# YTM32B1LE0 register map
Vendor: YTMicro; File version: 1.9
CPU: CM0PLUS r0p1, little endian, MPU, FPU, 2 interrupt priority bits
Registers are 32-bit, read-write, reset 0x0 unless marked. A register's access mark holds for its fields unless they carry their own. Offsets are from the block's base; [hi:lo] are bit positions; {n}, {i} and the like mark numbered series.

## PCTRLA — PORT Control
Base 0x40049000; register names take the prefix PCTRLA_
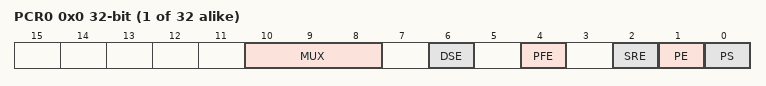
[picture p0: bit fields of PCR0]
{0x0+4i} PCR{i} (i=0..31) — Port control register
  [10:8] MUX — Not all pin muxing slots are implemented. Unimplemented pin muxing slots are reserved. Please refer to pinmux table for detailed peripheral functions. The corresponding pin is configured in the following pin muxing slot as follows:
    0=Alternative 0, analog function, digital function is disabled; 1=Alternative 1, GPIO function; {v}=Alternative {v} (v=2..7)
  [6] DSE — Drive strength configuration for digital pin muxing.
    0=Low drive strength, if the pin is configured as a digital output; 1=High drive strength, if the pin is configured as a digital output
  [4] PFE — Passive filter configuration for digital pin muxing.
    0=Passive input filter is disabled; 1=Passive input filter is enabled, if the pin is configured as a digital input
  [2] SRE — Slew rate configuration for digital pin muxing.
    0=Fast slew rate, if the pin is configured as a digital output; 1=Slow slew rate, if the pin is configured as a digital output
  [1] PE — Pull configuration for digital pin muxing.
    0=Internal pullup or pulldown resistor is not enabled; 1=Internal pullup or pulldown resistor is enabled
  [0] PS — Pull configuration for digital pin muxing.
    0=Internal pulldown resistor is enabled, if PE field is set; 1=Internal pullup resistor is enabled, if PE field is set

## PCTRLB — PORT Control
Base 0x4004A000; register names take the prefix PCTRLB_
Registers as PCTRLA.

## PCTRLC — PORT Control
Base 0x4004B000; register names take the prefix PCTRLC_
Registers as PCTRLA.

## PCTRLD — PORT Control
Base 0x4004C000; register names take the prefix PCTRLD_
Registers as PCTRLA.

## PCTRLE — PORT Control
Base 0x4004D000; register names take the prefix PCTRLE_
Registers as PCTRLA.

## TMU — Trigger Multiplexer Module
Base 0x40063000; register names take the prefix TMU_
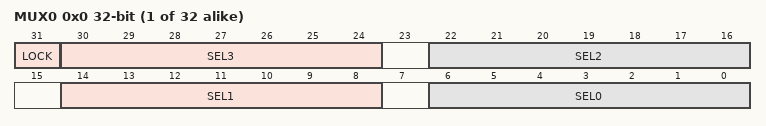
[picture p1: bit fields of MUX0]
{0x0+4i} MUX{i} (i=0..31)
  [31] LOCK — Lock the MUX select for peripheral trigger input
  [8n+6:8n] SEL{n} (n=0..3) — This read/write bit field is used to configure the MUX select for peripheral trigger input.

## IPC — IP Clock Control
Base 0x40065000; register names take the prefix IPC_
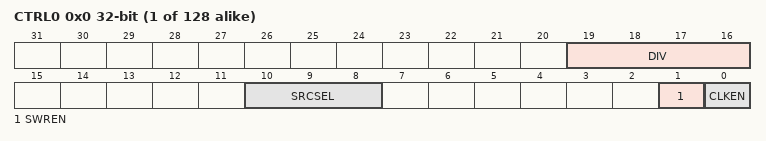
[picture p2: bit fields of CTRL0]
{0x0+4i} CTRL{i} (i=0..127)
  [19:16] DIV — The divide value = register value + 1
    {v}=Divided by {v+1} (v=0..15)
  [10:8] SRCSEL
    1=Select FIRC; 2=Select SIRC; 3=Select FXOSC; 4=Select SXOSC; 5=Select LPO
  [1] SWREN
    0=Software reset is de-asserted; 1=Software reset is asserted
  [0] CLKEN
    0=IP clock is disabled; 1=IP clock is enabled

## RCU — Reset Contru Unit of Microcontroller
Base 0x4007F000; register names take the prefix RCU_
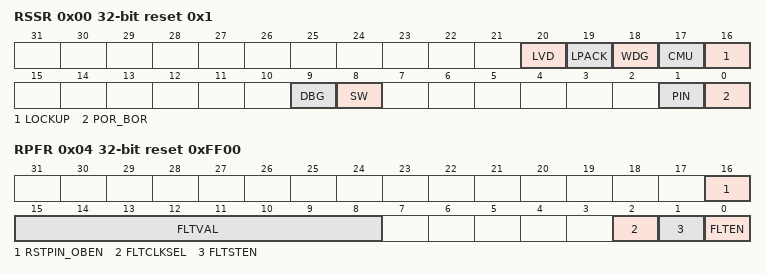
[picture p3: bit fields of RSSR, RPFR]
0x00 RSSR reset 0x1 — This register includes read-only status flags to indicate the source of the most recent reset. Multiple flags will be set if multiple reset events occur at the same time.
  [20] LVD — System reset caused by Low Voltage Detect.
    0=System reset not caused by Low Voltage Detect; 1=System reset caused by Low Voltage Detect
  [19] LPACK — System reset caused by Deepsleep/Standby acknowledge timeout. Indicates that after an attempt to enter Deepsleep/Standby mode, a reset has been caused by a failure of one or more peripherals to acknowledge.
    0=System reset not caused by Deepsleep/Standby acknowledge timeout; 1=System reset caused by Deepsleep/Standby acknowledge timeout
  [18] WDG — System reset caused by Clock Monitor Watchdog.
    0=System reset not caused by WDG; 1=System reset caused by WDG
  [17] CMU — System reset caused by Clock Monitor if CMURE is set.
    0=System reset not caused by CMU; 1=System reset caused by CMU
  [16] LOCKUP — System reset caused by ARM Core Lockup.
    0=System reset not caused by Lockup; 1=System reset caused by Lockup
  [9] DBG — System reset caused by Debug.
    0=System reset not caused by debug; 1=System reset caused by debug
  [8] SW — System reset caused by software to set SYSRESETREQ of ARM Core.
    0=System reset not caused by SW; 1=System reset caused by SW
  [1] PIN — System reset caused by RESET_b pin.
    0=System reset not caused by PIN; 1=System reset caused by PIN
  [0] POR_BOR — System reset caused by POR or BOR.
    0=System reset not caused by BOR or LVD; 1=System reset caused by BOR or LVD
0x04 RPFR reset 0xFF00 — This register controls the reset pin filter functions.
  [16] RSTPIN_OBEN — Enable bit of Reset pin output
    0=Not output low on reset pin when chip reset occurs; 1=Output low on reset pin when chip reset occurs
  [15:8] FLTVAL — FLTVAL control the filter counter value of SIRC/LPO clock cycles. 00000000b - Filter counter value is 0 00000001b - Filter counter value is 1 ... 11111111b - Filter counter value is 255
  [2] FLTCLKSEL — Select LPO_CLK and SIRC_CLK as Reset pin filter clock source
    0=Select LPO_CLK as Reset pin filter clock; 1=Select SIRC_CLK as Reset pin filter clock
  [1] FLTSTEN — Enable bit of Reset pin filter in deepsleep and standby mode, this bit should be set if filter need to be used in deepsleep and standby mode. This bit has no effect of reset pin filter in RUN mode
    0=Disable reset pin filter in deepsleep and standby mode; 1=Enable reset pin filter in deepsleep and standby mode if FLTEN is set
  [0] FLTEN — Enable bit of Reset pin filter, this bit should be set if filter need to be used.
    0=Disable reset pin filter; 1=Enable reset pin filter
